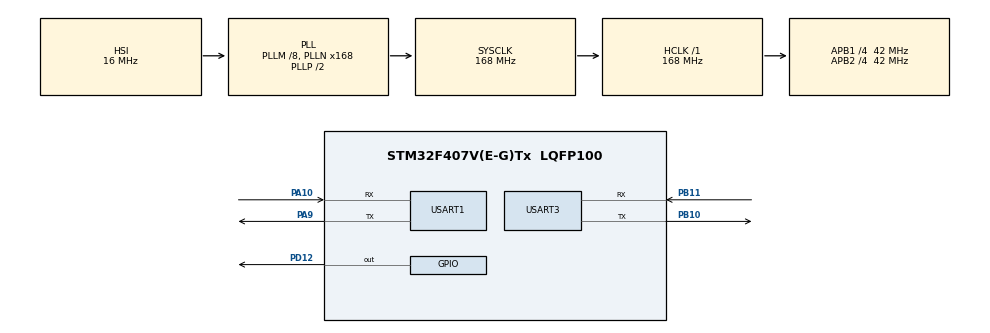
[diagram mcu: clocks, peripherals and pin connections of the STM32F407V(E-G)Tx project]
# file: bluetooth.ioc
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Mcu.Family=STM32F4
Mcu.Name=STM32F407V(E-G)Tx
Mcu.Package=LQFP100
NVIC.PriorityGroup=NVIC_PRIORITYGROUP_0
NVIC.TIM1_UP_TIM10_IRQn=true\:0\:0\:false\:false\:true\:false\:true
NVIC.TimeBase=TIM1_UP_TIM10_IRQn
NVIC.TimeBaseIP=TIM1
NVIC.USART1_IRQn=true\:0\:0\:false\:false\:true\:true\:true
NVIC.USART3_IRQn=true\:0\:0\:false\:false\:true\:true\:true
PA10.Mode=Asynchronous
PA10.Signal=USART1_RX
PA9.Mode=Asynchronous
PA9.Signal=USART1_TX
PB10.Mode=Asynchronous
PB10.Signal=USART3_TX
PB11.Mode=Asynchronous
PB11.Signal=USART3_RX
PD12.Signal=GPIO_Output
ProjectManager.HeapSize=0x200
ProjectManager.StackSize=0x400
ProjectManager.TargetToolchain=STM32CubeIDE
RCC.48MHZClocksFreq_Value=48000000
RCC.AHBFreq_Value=168000000
RCC.APB1CLKDivider=RCC_HCLK_DIV4
RCC.APB1Freq_Value=42000000
RCC.APB1TimFreq_Value=84000000
RCC.APB2CLKDivider=RCC_HCLK_DIV4
RCC.APB2Freq_Value=42000000
RCC.APB2TimFreq_Value=84000000
RCC.CortexFreq_Value=168000000
RCC.HCLKFreq_Value=168000000
RCC.HSE_VALUE=8000000
RCC.HSI_VALUE=16000000
RCC.LSE_VALUE=32768
RCC.PLLM=8
RCC.PLLN=168
RCC.PLLQ=7
RCC.SYSCLKFreq_VALUE=168000000
RCC.SYSCLKSource=RCC_SYSCLKSOURCE_PLLCLK
RCC.VCOOutputFreq_Value=336000000
USART1.VirtualMode=VM_ASYNC
USART3.VirtualMode=VM_ASYNC
VP_SYS_VS_tim1.Mode=TIM1
board=STM32F407G-DISC1

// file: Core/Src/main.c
/* USER CODE BEGIN Header */
/**
  ******************************************************************************
  * @file           : main.c
  * @brief          : Main program body
  ******************************************************************************
  * @attention
  *
  * <h2><center>&copy; Copyright (c) 2024 STMicroelectronics.
  * All rights reserved.</center></h2>
  *
  * This software component is licensed by ST under BSD 3-Clause license,
  * the "License"; You may not use this file except in compliance with the
  * License. You may obtain a copy of the License at:
  *                        opensource.org/licenses/BSD-3-Clause
  *
  ******************************************************************************
  */
/* USER CODE END Header */
#include "main.h"

UART_HandleTypeDef huart1;
UART_HandleTypeDef huart3;

void SystemClock_Config(void);
static void MX_GPIO_Init(void);
static void MX_USART1_UART_Init(void);
static void MX_USART3_UART_Init(void);
uint8_t rx_data;

int main(void)
{

  /* MCU Configuration--------------------------------------------------------*/

  /* Reset of all peripherals, Initializes the Flash interface and the Systick. */
  HAL_Init();

  /* Configure the system clock */
  SystemClock_Config();

  /* Initialize all configured peripherals */
  MX_GPIO_Init();
  MX_USART1_UART_Init();
  MX_USART3_UART_Init();

  HAL_UART_Receive_IT(&huart1,&rx_data,1);

  /* Infinite loop */
  while (1)
  {

  }
}

void SystemClock_Config(void)
{
  RCC_OscInitTypeDef RCC_OscInitStruct = {0};
  RCC_ClkInitTypeDef RCC_ClkInitStruct = {0};

  /** Configure the main internal regulator output voltage
  */
  __HAL_RCC_PWR_CLK_ENABLE();
  __HAL_PWR_VOLTAGESCALING_CONFIG(PWR_REGULATOR_VOLTAGE_SCALE1);
  /** Initializes the RCC Oscillators according to the specified parameters
  * in the RCC_OscInitTypeDef structure.
  */
  RCC_OscInitStruct.OscillatorType = RCC_OSCILLATORTYPE_HSI;
  RCC_OscInitStruct.HSIState = RCC_HSI_ON;
  RCC_OscInitStruct.HSICalibrationValue = RCC_HSICALIBRATION_DEFAULT;
  RCC_OscInitStruct.PLL.PLLState = RCC_PLL_ON;
  RCC_OscInitStruct.PLL.PLLSource = RCC_PLLSOURCE_HSI;
  RCC_OscInitStruct.PLL.PLLM = 8;
  RCC_OscInitStruct.PLL.PLLN = 168;
  RCC_OscInitStruct.PLL.PLLP = RCC_PLLP_DIV2;
  RCC_OscInitStruct.PLL.PLLQ = 7;
  if (HAL_RCC_OscConfig(&RCC_OscInitStruct) != HAL_OK)
  {
    Error_Handler();
  }
  /** Initializes the CPU, AHB and APB buses clocks
  */
  RCC_ClkInitStruct.ClockType = RCC_CLOCKTYPE_HCLK|RCC_CLOCKTYPE_SYSCLK
                              |RCC_CLOCKTYPE_PCLK1|RCC_CLOCKTYPE_PCLK2;
  RCC_ClkInitStruct.SYSCLKSource = RCC_SYSCLKSOURCE_PLLCLK;
  RCC_ClkInitStruct.AHBCLKDivider = RCC_SYSCLK_DIV1;
  RCC_ClkInitStruct.APB1CLKDivider = RCC_HCLK_DIV4;
  RCC_ClkInitStruct.APB2CLKDivider = RCC_HCLK_DIV4;

  if (HAL_RCC_ClockConfig(&RCC_ClkInitStruct, FLASH_LATENCY_5) != HAL_OK)
  {
    Error_Handler();
  }
}

static void MX_USART1_UART_Init(void)
{

  huart1.Instance = USART1;
  huart1.Init.BaudRate = 115200;
  huart1.Init.WordLength = UART_WORDLENGTH_8B;
  huart1.Init.StopBits = UART_STOPBITS_1;
  huart1.Init.Parity = UART_PARITY_NONE;
  huart1.Init.Mode = UART_MODE_TX_RX;
  huart1.Init.HwFlowCtl = UART_HWCONTROL_NONE;
  huart1.Init.OverSampling = UART_OVERSAMPLING_16;
  if (HAL_UART_Init(&huart1) != HAL_OK)
  {
    Error_Handler();
  }

}

static void MX_USART3_UART_Init(void)
{

  huart3.Instance = USART3;
  huart3.Init.BaudRate = 115200;
  huart3.Init.WordLength = UART_WORDLENGTH_8B;
  huart3.Init.StopBits = UART_STOPBITS_1;
  huart3.Init.Parity = UART_PARITY_NONE;
  huart3.Init.Mode = UART_MODE_TX_RX;
  huart3.Init.HwFlowCtl = UART_HWCONTROL_NONE;
  huart3.Init.OverSampling = UART_OVERSAMPLING_16;
  if (HAL_UART_Init(&huart3) != HAL_OK)
  {
    Error_Handler();
  }

}

static void MX_GPIO_Init(void)
{
  GPIO_InitTypeDef GPIO_InitStruct = {0};

  /* GPIO Ports Clock Enable */
  __HAL_RCC_GPIOB_CLK_ENABLE();
  __HAL_RCC_GPIOD_CLK_ENABLE();
  __HAL_RCC_GPIOA_CLK_ENABLE();

  /*Configure GPIO pin Output Level */
  HAL_GPIO_WritePin(GPIOD, GPIO_PIN_12, GPIO_PIN_RESET);

  /*Configure GPIO pin : PD12 */
  GPIO_InitStruct.Pin = GPIO_PIN_12;
  GPIO_InitStruct.Mode = GPIO_MODE_OUTPUT_PP;
  GPIO_InitStruct.Pull = GPIO_NOPULL;
  GPIO_InitStruct.Speed = GPIO_SPEED_FREQ_LOW;
  HAL_GPIO_Init(GPIOD, &GPIO_InitStruct);

}

/* USER CODE BEGIN 4 */
void HAL_UART_RxCpltCallback(UART_HandleTypeDef *huart)
{
	if(huart->Instance==USART1)
	  {
		if(rx_data == 'F')
		    {
			HAL_GPIO_WritePin(GPIOD, GPIO_PIN_12, SET);
		    }
		else if(rx_data == 'B')
		{
			HAL_GPIO_WritePin(GPIOD, GPIO_PIN_12, RESET);
		}
		HAL_UART_Receive_IT(&huart1,&rx_data,1);
	  }
}
/* USER CODE END 4 */

void HAL_TIM_PeriodElapsedCallback(TIM_HandleTypeDef *htim)
{
  if (htim->Instance == TIM1) {
    HAL_IncTick();
  }
}

void Error_Handler(void)
{
  __disable_irq();
  while (1)
  {
  }
}

/************************ (C) COPYRIGHT STMicroelectronics *****END OF FILE****/
